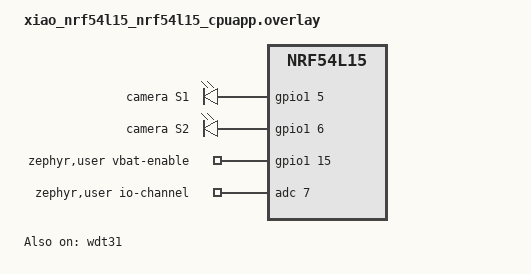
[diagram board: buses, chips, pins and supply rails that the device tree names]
/* Perfboard variant, see ../../notes/perfboard.md */
#include <zephyr/dt-bindings/gpio/nordic-nrf-gpio.h>

/ {
	outputs {
		compatible = "gpio-leds";
		s1_drv: s1 {
			gpios = <&gpio1 5 (GPIO_ACTIVE_HIGH | NRF_GPIO_DRIVE_S0H1)>;	/* D1 */
			label = "camera S1";
		};
		s2_drv: s2 {
			gpios = <&gpio1 6 (GPIO_ACTIVE_HIGH | NRF_GPIO_DRIVE_S0H1)>;	/* D2 */
			label = "camera S2";
		};
	};

	/* LiPo behind a load switch and a 1:2 divider into AIN7 (Seeed's sample scales by 2) */
	zephyr,user {
		io-channels = <&adc 7>;
		vbat-enable-gpios = <&gpio1 15 GPIO_ACTIVE_HIGH>;
		vbat-divider = <2>;
		vbat-empty-mv = <3300>;
		vbat-full-mv = <4150>;
	};
};

/* the firmware switches the divider itself, so it draws nothing between readings */
&vbat_pwr {
	status = "disabled";
};

/* USR button on P0.00 via SENSE, as on the coin-cell board */
&gpio0 {
	sense-edge-mask = <(1 << 0)>;
	latch-detect;
};

&wdt31 {
	status = "okay";
};
